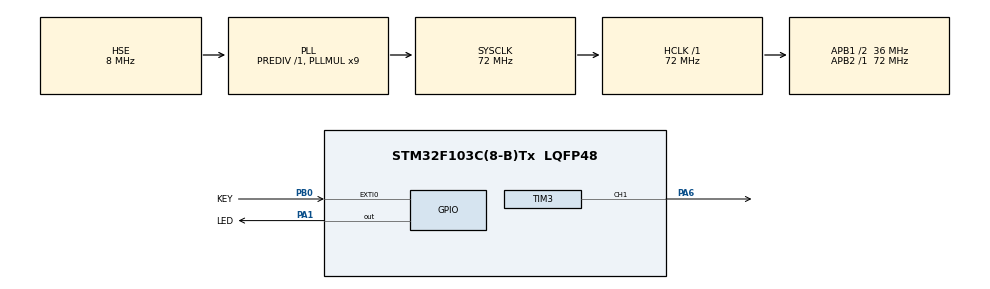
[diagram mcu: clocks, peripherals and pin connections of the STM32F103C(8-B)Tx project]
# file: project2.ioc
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Mcu.Family=STM32F1
Mcu.Name=STM32F103C(8-B)Tx
Mcu.Package=LQFP48
NVIC.EXTI0_IRQn=true\:0\:0\:false\:false\:true\:true\:true\:true
NVIC.PriorityGroup=NVIC_PRIORITYGROUP_4
NVIC.TIM1_UP_IRQn=true\:6\:0\:false\:false\:true\:true\:true\:true
NVIC.TIM3_IRQn=true\:0\:0\:false\:false\:true\:true\:true\:true
PA1.GPIO_Label=LED
PA1.Signal=GPIO_Output
PA13.Mode=Serial_Wire
PA13.Signal=SYS_JTMS-SWDIO
PA14.Mode=Serial_Wire
PA14.Signal=SYS_JTCK-SWCLK
PA6.Signal=S_TIM3_CH1
PB0.GPIO_Label=KEY
PB0.GPIO_PuPd=GPIO_PULLUP
PB0.GPIO_ModeDefaultEXTI=GPIO_MODE_IT_FALLING
PB0.Signal=GPXTI0
PC14-OSC32_IN.Mode=LSE-External-Oscillator
PC14-OSC32_IN.Signal=RCC_OSC32_IN
PC15-OSC32_OUT.Mode=LSE-External-Oscillator
PC15-OSC32_OUT.Signal=RCC_OSC32_OUT
PD0-OSC_IN.Mode=HSE-External-Oscillator
PD0-OSC_IN.Signal=RCC_OSC_IN
PD1-OSC_OUT.Mode=HSE-External-Oscillator
PD1-OSC_OUT.Signal=RCC_OSC_OUT
ProjectManager.HeapSize=0x200
ProjectManager.StackSize=0x400
ProjectManager.TargetToolchain=MDK-ARM V5.32
RCC.AHBFreq_Value=72000000
RCC.APB1CLKDivider=RCC_HCLK_DIV2
RCC.APB1Freq_Value=36000000
RCC.APB1TimFreq_Value=72000000
RCC.APB2Freq_Value=72000000
RCC.APB2TimFreq_Value=72000000
RCC.HCLKFreq_Value=72000000
RCC.PLLMUL=RCC_PLL_MUL9
RCC.PLLSourceVirtual=RCC_PLLSOURCE_HSE
RCC.SYSCLKFreq_VALUE=72000000
RCC.SYSCLKSource=RCC_SYSCLKSOURCE_PLLCLK
RCC.USBFreq_Value=72000000
SH.S_TIM3_CH1.0=TIM3_CH1,PWM Generation1 CH1
TIM1.AutoReloadPreload=TIM_AUTORELOAD_PRELOAD_ENABLE
TIM1.Period=49999
TIM1.Prescaler=7199
TIM3.Channel-PWM\ Generation1\ CH1=TIM_CHANNEL_1
VP_TIM1_VS_ClockSourceINT.Mode=Internal
VP_TIM3_VS_ClockSourceINT.Mode=Internal
board=custom

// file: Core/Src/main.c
/* USER CODE BEGIN Header */
/**
  ******************************************************************************
  * @file           : main.c
  * @brief          : Main program body
  ******************************************************************************
  * @attention
  *
  * Copyright (c) 2026 STMicroelectronics.
  * All rights reserved.
  *
  * This software is licensed under terms that can be found in the LICENSE file
  * in the root directory of this software component.
  * If no LICENSE file comes with this software, it is provided AS-IS.
  *
  ******************************************************************************
  */
/* USER CODE END Header */
#include "main.h"
#include "tim.h"
#include "gpio.h"

/* USER CODE BEGIN PD */
/* Breathing light timing.
   One ramp = BREATH_MAX / BREATH_STEP = 250 ticks, 250 x 6 ms = 1.5 s,
   so a full bright->dark->bright cycle takes 3 s. */
#define BREATH_MAX       999U   /* PWM period in counter ticks (TIM1 ARR) */
#define BREATH_STEP      4U     /* brightness change per tick            */
#define BREATH_TICK_MS   6U     /* time between two updates (ms)         */
/* USER CODE END PD */

void SystemClock_Config(void);

int main(void)
{

  /* MCU Configuration--------------------------------------------------------*/

  /* Reset of all peripherals, Initializes the Flash interface and the Systick. */
  HAL_Init();

  /* Configure the system clock */
  SystemClock_Config();

  /* Initialize all configured peripherals */
  MX_GPIO_Init();
  MX_TIM1_Init();
  MX_TIM3_Init();
  /* USER CODE BEGIN 2 */

  /* TIM1 channel 2 PWM on PA9: 72 MHz / 72 / 1000 = 1 kHz */
  HAL_TIM_PWM_Start(&htim1, TIM_CHANNEL_2);

/* USER CODE END 2 */

  /* Infinite loop */
  while (1)
  {

    /* USER CODE BEGIN 3 */
    /* Breathing. The LED anode is on 3.3 V and the cathode on PA9, so the
       pin sinks the current: a LOW level lights the LED, i.e.
       brightness = 100 % - duty. Hence CCR = BREATH_MAX - level. */
    static int32_t level = 0;
    static int32_t dir   = 1;

    level += dir * (int32_t)BREATH_STEP;
    if (level >= (int32_t)BREATH_MAX) { level = (int32_t)BREATH_MAX; dir = -1; }
    if (level <= 0)                   { level = 0;                    dir =  1; }

    __HAL_TIM_SET_COMPARE(&htim1, TIM_CHANNEL_2, (uint32_t)((int32_t)BREATH_MAX - level));
    HAL_Delay(BREATH_TICK_MS);
  }
  /* USER CODE END 3 */
}

void SystemClock_Config(void)
{
  RCC_OscInitTypeDef RCC_OscInitStruct = {0};
  RCC_ClkInitTypeDef RCC_ClkInitStruct = {0};

  /** Initializes the RCC Oscillators according to the specified parameters
  * in the RCC_OscInitTypeDef structure.
  */
  RCC_OscInitStruct.OscillatorType = RCC_OSCILLATORTYPE_HSE;
  RCC_OscInitStruct.HSEState = RCC_HSE_ON;
  RCC_OscInitStruct.HSEPredivValue = RCC_HSE_PREDIV_DIV1;
  RCC_OscInitStruct.HSIState = RCC_HSI_ON;
  RCC_OscInitStruct.PLL.PLLState = RCC_PLL_ON;
  RCC_OscInitStruct.PLL.PLLSource = RCC_PLLSOURCE_HSE;
  RCC_OscInitStruct.PLL.PLLMUL = RCC_PLL_MUL9;
  if (HAL_RCC_OscConfig(&RCC_OscInitStruct) != HAL_OK)
  {
    Error_Handler();
  }

  /** Initializes the CPU, AHB and APB buses clocks
  */
  RCC_ClkInitStruct.ClockType = RCC_CLOCKTYPE_HCLK|RCC_CLOCKTYPE_SYSCLK
                              |RCC_CLOCKTYPE_PCLK1|RCC_CLOCKTYPE_PCLK2;
  RCC_ClkInitStruct.SYSCLKSource = RCC_SYSCLKSOURCE_PLLCLK;
  RCC_ClkInitStruct.AHBCLKDivider = RCC_SYSCLK_DIV1;
  RCC_ClkInitStruct.APB1CLKDivider = RCC_HCLK_DIV2;
  RCC_ClkInitStruct.APB2CLKDivider = RCC_HCLK_DIV1;

  if (HAL_RCC_ClockConfig(&RCC_ClkInitStruct, FLASH_LATENCY_2) != HAL_OK)
  {
    Error_Handler();
  }
}

void Error_Handler(void)
{
  __disable_irq();
  while (1)
  {
  }
}
